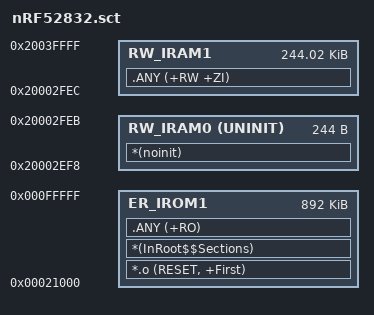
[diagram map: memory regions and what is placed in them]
LR_IROM1 0x21000 0x00DF000  {
  ER_IROM1 0x21000 0x00DF000  {
   *.o (RESET, +First)
   *(InRoot$$Sections)
   .ANY (+RO)
  }
  RW_IRAM0 0x20002EF8 UNINIT 0x000000F4  { ;no init section
        *(noinit)
  }
  RW_IRAM1 0x20002FEC 0x0003D014  {
   .ANY (+RW +ZI)
  }
}
